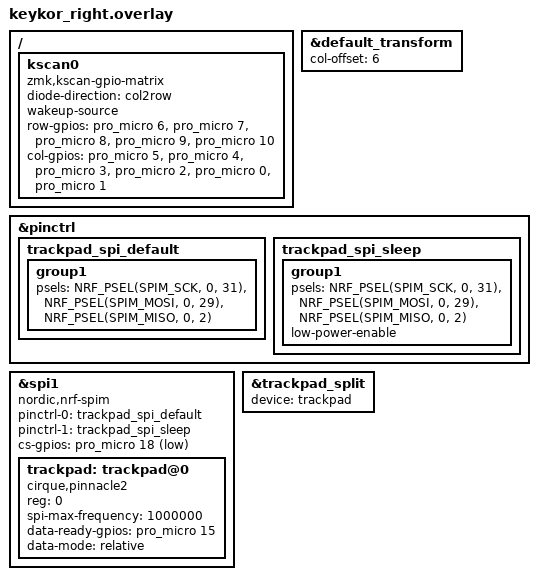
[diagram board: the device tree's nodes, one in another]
#include "keykor.dtsi" // The shared dtsi file is included in the overlay

&default_transform {
    col-offset = <6>;   // left half has 6 columns, so the right half starts at column 6
};

/ {
    kscan0: kscan0 {
        compatible = "zmk,kscan-gpio-matrix";
        diode-direction = "col2row";
        wakeup-source;

        row-gpios
            = <&pro_micro 6 (GPIO_ACTIVE_HIGH | GPIO_PULL_DOWN)>
            , <&pro_micro 7 (GPIO_ACTIVE_HIGH | GPIO_PULL_DOWN)>
            , <&pro_micro 8 (GPIO_ACTIVE_HIGH | GPIO_PULL_DOWN)>
            , <&pro_micro 9 (GPIO_ACTIVE_HIGH | GPIO_PULL_DOWN)>
            , <&pro_micro 10 (GPIO_ACTIVE_HIGH | GPIO_PULL_DOWN)>
            ;

        col-gpios
            = <&pro_micro 5 GPIO_ACTIVE_HIGH>
            , <&pro_micro 4 GPIO_ACTIVE_HIGH>
            , <&pro_micro 3 GPIO_ACTIVE_HIGH>
            , <&pro_micro 2 GPIO_ACTIVE_HIGH>
            , <&pro_micro 0 GPIO_ACTIVE_HIGH>
            , <&pro_micro 1 GPIO_ACTIVE_HIGH>
            ;
    };
};

// ---- Cirque Pinnacle trackpad (SPI) ----
// Your pinout -> nRF52840 port/pin (ZMK nice!nano pro_micro map; pinctrl needs the raw pins):
//   SCK D21 = P0.31, SI/MOSI D20 = P0.29, SO/MISO D19 = P0.02
//   SS D18 and DR D15 are set below with &pro_micro 18 / &pro_micro 15 (P1.15 / P1.13)
&pinctrl {
    // New labels (not the board's spi1_default) so this does not depend on the board's pinctrl names
    trackpad_spi_default: trackpad_spi_default {
        group1 {
            psels = <NRF_PSEL(SPIM_SCK, 0, 31)>,
                    <NRF_PSEL(SPIM_MOSI, 0, 29)>,
                    <NRF_PSEL(SPIM_MISO, 0, 2)>;
        };
    };

    trackpad_spi_sleep: trackpad_spi_sleep {
        group1 {
            psels = <NRF_PSEL(SPIM_SCK, 0, 31)>,
                    <NRF_PSEL(SPIM_MOSI, 0, 29)>,
                    <NRF_PSEL(SPIM_MISO, 0, 2)>;
            low-power-enable;
        };
    };
};

&spi1 {
    status = "okay";
    compatible = "nordic,nrf-spim";
    pinctrl-0 = <&trackpad_spi_default>;
    pinctrl-1 = <&trackpad_spi_sleep>;
    pinctrl-names = "default", "sleep";
    cs-gpios = <&pro_micro 18 GPIO_ACTIVE_LOW>;

    trackpad: trackpad@0 {
        compatible = "cirque,pinnacle2";
        reg = <0>;
        spi-max-frequency = <1000000>;
        status = "okay";
        data-ready-gpios = <&pro_micro 15 GPIO_ACTIVE_HIGH>;
        data-mode = "relative";
    };
};

&trackpad_split {
    device = <&trackpad>;
};
